# R7FA0E107 register map
Vendor: Renesas Electronics Corporation; Series: RA0; File version: 1.10.00
CPU: CM23 r1p0, little endian, no MPU, no FPU, VTOR, 2 interrupt priority bits, 64 interrupts
Registers are 16-bit, read-write, reset 0x0 unless marked. A register's access mark holds for its fields unless they carry their own. Offsets are from the block's base; [hi:lo] are bit positions; {n}, {i} and the like mark numbered series.

## DTC — Data Transfer Controller
Base 0x40005400
0x00 DTCCR 8-bit reset 0x8 — DTC Control Register
  [4] RRS — DTC Transfer Information Read Skip Enable
0x04 DTCVBR 32-bit — DTC Vector Base Register
0x0C DTCST 8-bit — DTC Module Start Register
  [0] DTCST — DTC Module Start
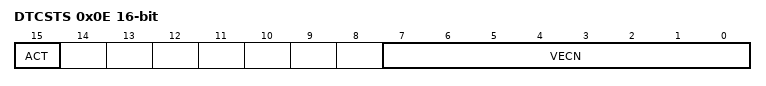
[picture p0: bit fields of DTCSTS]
0x0E DTCSTS ro — DTC Status Register
  [15] ACT — DTC Active Flag
  [7:0] VECN — DTC,Activating Vector Number Monitoring

## DBG — Debug Function
Base 0x4001B000
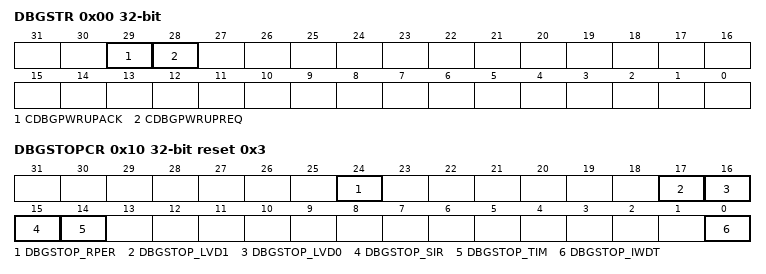
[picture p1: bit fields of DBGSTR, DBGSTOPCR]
0x00 DBGSTR 32-bit ro — Debug Status Register
  [29] CDBGPWRUPACK — Debug Power,up Acknowledge
  [28] CDBGPWRUPREQ — Debug Power,up Request
0x10 DBGSTOPCR 32-bit reset 0x3 — Debug Stop Control Register
  [24] DBGSTOP_RPER — Mask Bit for SRAM Parity Error Reset/Interrupt
  [17] DBGSTOP_LVD1 — Mask Bit for LVD1 Reset/Interrupt
  [16] DBGSTOP_LVD0 — Mask Bit for LVD0 Reset
  [15] DBGSTOP_SIR — Mask Bit for SAU, IICA, UARTA, PORT_IRQ0-5 Reset/Interrupt in the OCD brake mode. In the OCD break mode, the reset/interrupt is masked and each operation is stopped.
  [14] DBGSTOP_TIM
  [0] DBGSTOP_IWDT — Mask Bit for IWDT Reset/Interrupt in the OCD Run Mode

## ELC — Event Link Controller
Base 0x40041000
0x00 ELCR 8-bit — Event Link Controller Register
  [7] ELCON — All Event Link Enable
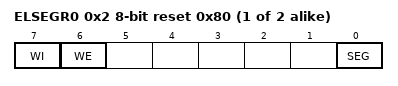
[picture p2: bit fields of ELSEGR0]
{0x2+2i} ELSEGR{i} (i=0..1) 8-bit reset 0x80 — Event Link Software Event Generation Register {i}
  [7] WI wo — ELSEGR Register Write Disable
  [6] WE — SEG Bit Write Enable
  [0] SEG wo — Software Event Generation
0x1C ELSR{i} (i=23..28; step 0x4) — Event Link Setting Register {i}
  [5:0] ELS — Event Link Select

## IWDT — Independent Watchdog Timer
Base 0x40044400
0x00 IWDTRR 8-bit reset 0xFF — IWDT Refresh Register
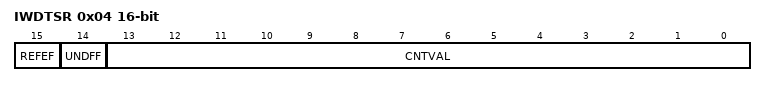
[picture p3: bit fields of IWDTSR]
0x04 IWDTSR — IWDT Status Register
  [15] REFEF — Refresh Error Flag
  [14] UNDFF — Underflow Flag
  [13:0] CNTVAL ro — Down,counter Value

## MSTP — Module Stop Control
Base 0x40047000
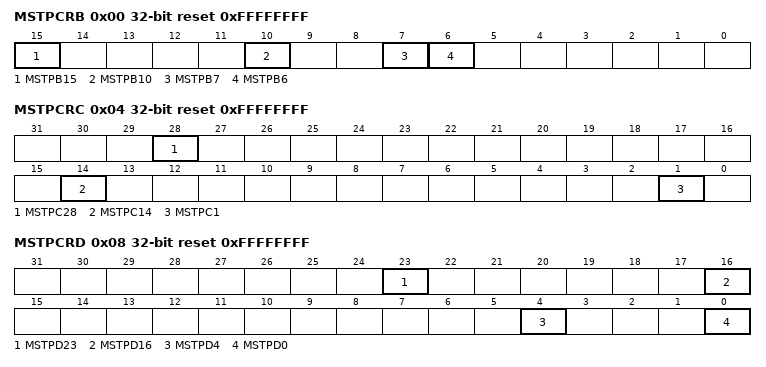
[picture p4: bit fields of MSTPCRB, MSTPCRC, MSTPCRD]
0x00 MSTPCRB 32-bit reset 0xFFFFFFFF — Module Stop Control Register B
  [15] MSTPB15 — Serial Interface UARTA Module Stop
  [10] MSTPB10 — I2C Bus Interface Module Stop
  [7] MSTPB7 — Serial Array Unit 1 Module Stop
  [6] MSTPB6 — Serial Array Unit 0 Module Stop
0x04 MSTPCRC 32-bit reset 0xFFFFFFFF — Module Stop Control Register C
  [28] MSTPC28 — True Random Number Generator Module Stop
  [14] MSTPC14 — Event Link Controller Module Stop
  [1] MSTPC1 — Cyclic Redundancy Check Calculator Module Stop
0x08 MSTPCRD 32-bit reset 0xFFFFFFFF — Module Stop Control Register D
  [23] MSTPD23 — Realtime Clock Module Stop
  [16] MSTPD16 — A/D Converter Module Stop
  [4] MSTPD4 — 32-bit Interval Timer Module Stop
  [0] MSTPD0 — Timer Array Unit 0 Module Stop

## CRC — CRC Calculator
Base 0x40074000
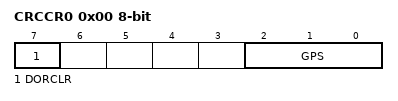
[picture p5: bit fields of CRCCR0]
0x00 CRCCR0 8-bit — CRC Control Register 0
  [7] DORCLR wo — CRCDOR/CRCDOR_HA Register Clear
  [2:0] GPS — CRC Generating Polynomial Switching
0x04 CRCDIR 32-bit — CRC Data Input Register
0x04 CRCDIR_BY 8-bit (alternate view of CRCDIR) — CRC Data Input Register
0x08 CRCDOR 32-bit — CRC Data Output Register
0x08 CRCDOR_HA (alternate view of CRCDOR) — CRC Data Output Register

## PORT0 — Port 0 Control
Base 0x400A0000
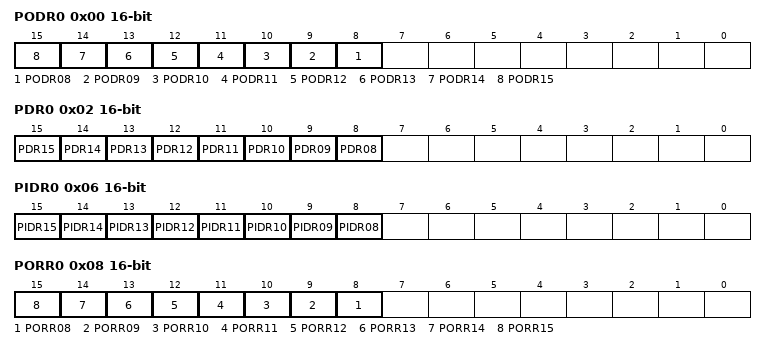
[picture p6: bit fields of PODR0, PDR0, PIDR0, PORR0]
0x00 PODR0 — Port 0 Output Data Register
  [n] PODR{n:02} (n=8..15) — P{n:03} Output Data
0x02 PDR0 — Port 0 Direction Register
  [n] PDR{n:02} (n=8..15) — P{n:03} Direction
0x06 PIDR0 ro — Port 0 State Register
  [n] PIDR{n:02} (n=8..15) — P{n:03} State
0x08 PORR0 wo — Port 0 Output Reset Register
  [n] PORR{n:02} (n=8..15) — P{n:03} Output Reset
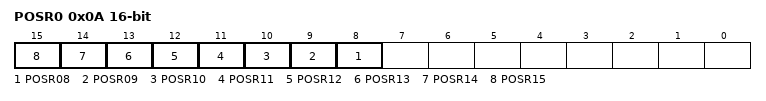
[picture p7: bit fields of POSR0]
0x0A POSR0 wo — Port 0 Output Set Register
  [n] POSR{n:02} (n=8..15) — P{n:03} Output Set
